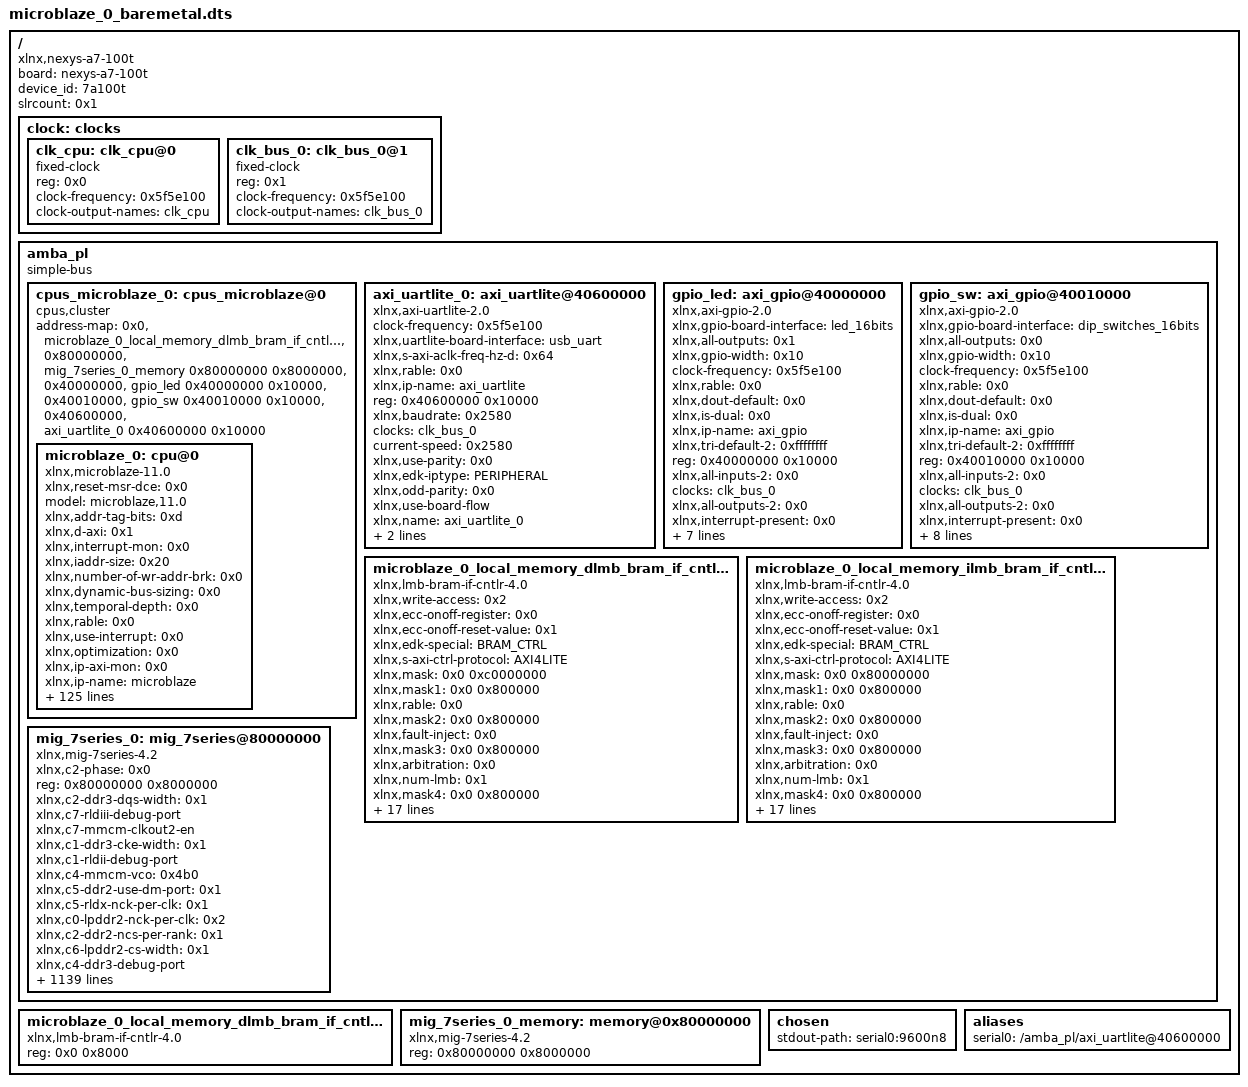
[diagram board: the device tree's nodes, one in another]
/dts-v1/;

/ {
        board = "nexys-a7-100t";
        compatible = "xlnx,nexys-a7-100t";
        device_id = "7a100t";
        #address-cells = <0x1>;
        #size-cells = <0x1>;
        slrcount = <0x1>;

        clock: clocks {
                #address-cells = <0x1>;
                #size-cells = <0x0>;
                phandle = <0x8>;

                clk_cpu: clk_cpu@0 {
                        compatible = "fixed-clock";
                        reg = <0x0>;
                        clock-frequency = <0x5f5e100>;
                        clock-output-names = "clk_cpu";
                        #clock-cells = <0x0>;
                        phandle = <0x9>;
                };

                clk_bus_0: clk_bus_0@1 {
                        compatible = "fixed-clock";
                        reg = <0x1>;
                        clock-frequency = <0x5f5e100>;
                        clock-output-names = "clk_bus_0";
                        #clock-cells = <0x0>;
                        phandle = <0x7>;
                };
        };

        amba_pl: amba_pl {
                ranges;
                compatible = "simple-bus";
                #address-cells = <0x1>;
                #size-cells = <0x1>;
                phandle = <0x6>;

                cpus_microblaze_0: cpus_microblaze@0 {
                        #cpu-mask-cells = <0x1>;
                        compatible = "cpus,cluster";
                        address-map = <0x0 &microblaze_0_local_memory_dlmb_bram_if_cntlr_memory 0x0 0x8000>,
                         <0x80000000 &mig_7series_0_memory 0x80000000 0x8000000>,
                         <0x40000000 &gpio_led 0x40000000 0x10000>,
                         <0x40010000 &gpio_sw 0x40010000 0x10000>,
                         <0x40600000 &axi_uartlite_0 0x40600000 0x10000>;
                        #ranges-address-cells = <0x1>;
                        #ranges-size-cells = <0x1>;
                        phandle = <0xa>;

                        microblaze_0: cpu@0 {
                                xlnx,reset-msr-dce = <0x0>;
                                model = "microblaze,11.0";
                                xlnx,addr-tag-bits = <0xd>;
                                xlnx,d-axi = <0x1>;
                                xlnx,interrupt-mon = <0x0>;
                                xlnx,iaddr-size = <0x20>;
                                xlnx,number-of-wr-addr-brk = <0x0>;
                                xlnx,dynamic-bus-sizing = <0x0>;
                                xlnx,temporal-depth = <0x0>;
                                xlnx,rable = <0x0>;
                                xlnx,use-interrupt = <0x0>;
                                xlnx,optimization = <0x0>;
                                xlnx,ip-axi-mon = <0x0>;
                                xlnx,ip-name = "microblaze";
                                d-cache-highaddr = <0x87ffffff>;
                                xlnx,dcache-force-tag-lutram = <0x0>;
                                xlnx,pc-width = <0x20>;
                                xlnx,interrupt-is-edge = <0x0>;
                                reg = <0x0>;
                                xlnx,async-interrupt = <0x1>;
                                xlnx,use-mmu = <0x0>;
                                xlnx,reset-msr-ee = <0x0>;
                                xlnx,icache-victims = <0x0>;
                                xlnx,use-reorder-instr = <0x1>;
                                xlnx,d-lmb-mon = <0x0>;
                                xlnx,d-lmb-protocol = <0x0>;
                                xlnx,ill-opcode-exception = <0x0>;
                                xlnx,dcache-always-used = <0x1>;
                                xlnx,use-div = <0x0>;
                                xlnx,dc-axi-mon = <0x0>;
                                xlnx,debug-trace-async-reset = <0x0>;
                                xlnx,trace = <0x0>;
                                xlnx,part = "xc7a100tcsg324-1";
                                i-cache-baseaddr = <0x80000000>;
                                xlnx,use-config-reset = <0x0>;
                                xlnx,pvr = <0x0>;
                                xlnx,i-lmb-mon = <0x0>;
                                xlnx,dcache-byte-size = <0x4000>;
                                xlnx,fault-tolerant = <0x0>;
                                xlnx,family = "artix7";
                                compatible = "xlnx,microblaze-11.0", "xlnx,microblaze";
                                xlnx,data-size = <0x20>;
                                xlnx,mmu-zones = <0x10>;
                                xlnx,debug-trace-size = <0x2000>;
                                xlnx,mmu-privileged-instr = <0x0>;
                                xlnx,enable-discrete-ports = <0x0>;
                                d-cache-line-size = <0x10>;
                                xlnx,d-lmb = <0x1>;
                                xlnx,sco = <0x0>;
                                xlnx,reset-msr-eip = <0x0>;
                                clock-frequency = <0x5f5e100>;
                                xlnx,debug-interface = <0x0>;
                                xlnx,use-ext-brk = <0x0>;
                                xlnx,daddr-size = <0x20>;
                                xlnx,debug-enabled = <0x1>;
                                xlnx,reset-msr-ice = <0x0>;
                                xlnx,num-sync-ff-dbg-trace-clk = <0x2>;
                                xlnx,i-lmb-protocol = <0x0>;
                                xlnx,endianness = <0x1>;
                                xlnx,fsl-exception = <0x0>;
                                i-cache-line-size = <0x10>;
                                xlnx,use-extended-fsl-instr = <0x0>;
                                xlnx,reset-msr = <0x0>;
                                xlnx,dp-axi-mon = <0x0>;
                                xlnx,branch-target-cache-size = <0x0>;
                                xlnx,dcache-use-writeback = <0x0>;
                                xlnx,div-zero-exception = <0x0>;
                                xlnx,mmu-tlb-access = <0x3>;
                                bus-handle = <0x6>;
                                xlnx,cache-byte-size = <0x4000>;
                                xlnx,pvr-user2 = <0x0>;
                                xlnx,opcode-0x0-illegal = <0x0>;
                                xlnx,icache-line-len = <0x4>;
                                xlnx,ecc-use-ce-exception = <0x0>;
                                xlnx,base-vectors = <0x0 0x0>;
                                xlnx,use-dcache = <0x1>;
                                xlnx,use-barrel = <0x0>;
                                xlnx,reset-msr-bip = <0x0>;
                                xlnx,edk-special = "microblaze";
                                xlnx,allow-dcache-wr = <0x1>;
                                xlnx,addr-size = <0x20>;
                                xlnx,debug-external-trace = <0x0>;
                                xlnx,piaddr-size = <0x20>;
                                i-cache-highaddr = <0x87ffffff>;
                                xlnx,num-sync-ff-clk-debug = <0x2>;
                                xlnx,debug-event-counters = <0x5>;
                                xlnx,fpu-exception = <0x0>;
                                xlnx,allow-icache-wr = <0x1>;
                                xlnx,i-axi = <0x0>;
                                xlnx,g-use-exceptions = <0x0>;
                                xlnx,icache-streams = <0x0>;
                                xlnx,g-template-list = <0x0>;
                                xlnx,dcache-line-len = <0x4>;
                                xlnx,num-sync-ff-clk = <0x2>;
                                xlnx,use-stack-protection = <0x0>;
                                xlnx,use-hw-mul = <0x0>;
                                xlnx,num-sync-ff-dbg-clk = <0x1>;
                                xlnx,interconnect = <0x2>;
                                xlnx,edk-iptype = "PROCESSOR";
                                i-cache-size = <0x4000>;
                                xlnx,debug-latency-counters = <0x1>;
                                xlnx,use-fpu = <0x0>;
                                xlnx,reset-msr-ie = <0x0>;
                                xlnx,edge-is-positive = <0x1>;
                                xlnx,use-pcmp-instr = <0x0>;
                                xlnx,use-icache = <0x1>;
                                d-cache-size = <0x4000>;
                                xlnx,async-wakeup = <0x3>;
                                xlnx,use-non-secure = <0x0>;
                                xlnx,dcache-addr-tag = <0xd>;
                                xlnx,number-of-rd-addr-brk = <0x0>;
                                d-cache-baseaddr = <0x80000000>;
                                xlnx,area-optimized = <0x0>;
                                xlnx,avoid-primitives = <0x0>;
                                xlnx,lockstep-slave = <0x0>;
                                xlnx,use-ext-nm-brk = <0x0>;
                                xlnx,instr-size = <0x20>;
                                xlnx,icache-always-used = <0x1>;
                                xlnx,i-lmb = <0x1>;
                                xlnx,mmu-dtlb-size = <0x4>;
                                xlnx,lockstep-select = <0x0>;
                                xlnx,lmb-data-size = <0x20>;
                                xlnx,ic-axi-mon = <0x0>;
                                xlnx,num-sync-ff-clk-irq = <0x1>;
                                xlnx,fsl-links = <0x0>;
                                timebase-frequency = <0x5f5e100>;
                                xlnx,icache-force-tag-lutram = <0x0>;
                                xlnx,dcache-data-width = <0x0>;
                                xlnx,dcache-victims = <0x0>;
                                xlnx,use-branch-target-cache = <0x0>;
                                xlnx,debug-profile-size = <0x0>;
                                xlnx,unaligned-exceptions = <0x0>;
                                xlnx,lockstep-master = <0x0>;
                                xlnx,freq = <0x5f5e100>;
                                xlnx,number-of-pc-brk = <0x1>;
                                xlnx,mmu-itlb-size = <0x2>;
                                xlnx,imprecise-exceptions = <0x0>;
                                xlnx,use-msr-instr = <0x0>;
                                xlnx,icache-data-width = <0x0>;
                                xlnx,debug-counter-width = <0x20>;
                                phandle = <0xb>;
                        };
                };

                axi_uartlite_0: axi_uartlite@40600000 {
                        compatible = "xlnx,axi-uartlite-2.0", "xlnx,xps-uartlite-1.00.a";
                        clock-frequency = <0x5f5e100>;
                        xlnx,uartlite-board-interface = "usb_uart";
                        xlnx,s-axi-aclk-freq-hz-d = <0x64>;
                        xlnx,rable = <0x0>;
                        xlnx,ip-name = "axi_uartlite";
                        reg = <0x40600000 0x10000>;
                        xlnx,baudrate = <0x2580>;
                        clocks = <&clk_bus_0>;
                        current-speed = <0x2580>;
                        xlnx,use-parity = <0x0>;
                        xlnx,edk-iptype = "PERIPHERAL";
                        xlnx,odd-parity = <0x0>;
                        status = "okay";
                        xlnx,use-board-flow;
                        xlnx,name = "axi_uartlite_0";
                        xlnx,data-bits = <0x8>;
                        xlnx,parity = "No_Parity";
                        phandle = <0x5>;
                };

                gpio_led: axi_gpio@40000000 {
                        xlnx,gpio-board-interface = "led_16bits";
                        compatible = "xlnx,axi-gpio-2.0", "xlnx,xps-gpio-1.00.a";
                        xlnx,all-outputs = <0x1>;
                        xlnx,gpio-width = <0x10>;
                        clock-frequency = <0x5f5e100>;
                        xlnx,rable = <0x0>;
                        xlnx,dout-default = <0x0>;
                        xlnx,is-dual = <0x0>;
                        xlnx,ip-name = "axi_gpio";
                        xlnx,tri-default-2 = <0xffffffff>;
                        reg = <0x40000000 0x10000>;
                        xlnx,all-inputs-2 = <0x0>;
                        clocks = <&clk_bus_0>;
                        xlnx,all-outputs-2 = <0x0>;
                        xlnx,interrupt-present = <0x0>;
                        xlnx,gpio2-board-interface = "Custom";
                        xlnx,edk-iptype = "PERIPHERAL";
                        xlnx,dout-default-2 = <0x0>;
                        xlnx,gpio2-width = <0x20>;
                        status = "okay";
                        clock-names = "s_axi_aclk";
                        xlnx,tri-default = <0xffffffff>;
                        xlnx,name = "gpio_led";
                        xlnx,all-inputs = <0x0>;
                        phandle = <0x3>;
                };

                gpio_sw: axi_gpio@40010000 {
                        xlnx,gpio-board-interface = "dip_switches_16bits";
                        compatible = "xlnx,axi-gpio-2.0", "xlnx,xps-gpio-1.00.a";
                        xlnx,all-outputs = <0x0>;
                        xlnx,gpio-width = <0x10>;
                        clock-frequency = <0x5f5e100>;
                        xlnx,rable = <0x0>;
                        xlnx,dout-default = <0x0>;
                        xlnx,is-dual = <0x0>;
                        xlnx,ip-name = "axi_gpio";
                        xlnx,tri-default-2 = <0xffffffff>;
                        reg = <0x40010000 0x10000>;
                        xlnx,all-inputs-2 = <0x0>;
                        clocks = <&clk_bus_0>;
                        xlnx,all-outputs-2 = <0x0>;
                        xlnx,interrupt-present = <0x0>;
                        xlnx,gpio2-board-interface = "Custom";
                        xlnx,edk-iptype = "PERIPHERAL";
                        xlnx,dout-default-2 = <0x0>;
                        xlnx,gpio2-width = <0x20>;
                        status = "okay";
                        clock-names = "s_axi_aclk";
                        xlnx,use-board-flow;
                        xlnx,tri-default = <0xffffffff>;
                        xlnx,name = "gpio_sw";
                        xlnx,all-inputs = <0x1>;
                        phandle = <0x4>;
                };

                microblaze_0_local_memory_dlmb_bram_if_cntlr: lmb_bram_if_cntlr@0 {
                        xlnx,write-access = <0x2>;
                        compatible = "xlnx,lmb-bram-if-cntlr-4.0";
                        xlnx,ecc-onoff-register = <0x0>;
                        xlnx,ecc-onoff-reset-value = <0x1>;
                        xlnx,edk-special = "BRAM_CTRL";
                        xlnx,s-axi-ctrl-protocol = "AXI4LITE";
                        xlnx,mask = <0x0 0xc0000000>;
                        xlnx,mask1 = <0x0 0x800000>;
                        xlnx,rable = <0x0>;
                        xlnx,mask2 = <0x0 0x800000>;
                        xlnx,fault-inject = <0x0>;
                        xlnx,mask3 = <0x0 0x800000>;
                        xlnx,arbitration = <0x0>;
                        xlnx,num-lmb = <0x1>;
                        xlnx,mask4 = <0x0 0x800000>;
                        reg = <0x0 0x8000>;
                        xlnx,s-axi-ctrl-addr-width = <0x20>;
                        xlnx,mask5 = <0x0 0x800000>;
                        xlnx,ecc-status-registers = <0x0>;
                        xlnx,mask6 = <0x0 0x800000>;
                        xlnx,lmb-protocol = <0x0>;
                        xlnx,ce-counter-width = <0x0>;
                        xlnx,mask7 = <0x0 0x800000>;
                        xlnx,ecc = <0x0>;
                        xlnx,lmb-dwidth = <0x20>;
                        xlnx,interconnect = <0x0>;
                        xlnx,ce-failing-registers = <0x0>;
                        xlnx,edk-iptype = "PERIPHERAL";
                        xlnx,ue-failing-registers = <0x0>;
                        xlnx,s-axi-ctrl-data-width = <0x20>;
                        xlnx,bram-awidth = <0x20>;
                        xlnx,lmb-awidth = <0x20>;
                        phandle = <0xc>;
                };

                microblaze_0_local_memory_ilmb_bram_if_cntlr: lmb_bram_if_cntlr@1 {
                        xlnx,write-access = <0x2>;
                        compatible = "xlnx,lmb-bram-if-cntlr-4.0";
                        xlnx,ecc-onoff-register = <0x0>;
                        xlnx,ecc-onoff-reset-value = <0x1>;
                        xlnx,edk-special = "BRAM_CTRL";
                        xlnx,s-axi-ctrl-protocol = "AXI4LITE";
                        xlnx,mask = <0x0 0x80000000>;
                        xlnx,mask1 = <0x0 0x800000>;
                        xlnx,rable = <0x0>;
                        xlnx,mask2 = <0x0 0x800000>;
                        xlnx,fault-inject = <0x0>;
                        xlnx,mask3 = <0x0 0x800000>;
                        xlnx,arbitration = <0x0>;
                        xlnx,num-lmb = <0x1>;
                        xlnx,mask4 = <0x0 0x800000>;
                        reg = <0x0 0x8000>;
                        xlnx,s-axi-ctrl-addr-width = <0x20>;
                        xlnx,mask5 = <0x0 0x800000>;
                        xlnx,ecc-status-registers = <0x0>;
                        xlnx,mask6 = <0x0 0x800000>;
                        xlnx,lmb-protocol = <0x0>;
                        xlnx,ce-counter-width = <0x0>;
                        xlnx,mask7 = <0x0 0x800000>;
                        xlnx,ecc = <0x0>;
                        xlnx,lmb-dwidth = <0x20>;
                        xlnx,interconnect = <0x0>;
                        xlnx,ce-failing-registers = <0x0>;
                        xlnx,edk-iptype = "PERIPHERAL";
                        xlnx,ue-failing-registers = <0x0>;
                        xlnx,s-axi-ctrl-data-width = <0x20>;
                        xlnx,bram-awidth = <0x20>;
                        xlnx,lmb-awidth = <0x20>;
                        phandle = <0xd>;
                };

                mig_7series_0: mig_7series@80000000 {
                        xlnx,c2-phase = <0x0>;
                        reg = <0x80000000 0x8000000>;
                        xlnx,c2-ddr3-dqs-width = <0x1>;
                        xlnx,c7-rldiii-debug-port;
                        xlnx,c7-mmcm-clkout2-en;
                        xlnx,c1-ddr3-cke-width = <0x1>;
                        xlnx,c1-rldii-debug-port;
                        xlnx,c4-mmcm-vco = <0x4b0>;
                        xlnx,c5-ddr2-use-dm-port = <0x1>;
                        xlnx,c5-rldx-nck-per-clk = <0x1>;
                        xlnx,c0-lpddr2-nck-per-clk = <0x2>;
                        xlnx,c2-ddr2-ncs-per-rank = <0x1>;
                        xlnx,c6-lpddr2-cs-width = <0x1>;
                        xlnx,c4-ddr3-debug-port;
                        xlnx,c4-lpddr2-dqs-cnt-width = <0x1>;
                        xlnx,c5-ddr2-use-cs-port = <0x1>;
                        xlnx,mmcm-clkout0-en;
                        xlnx,ddr2-addr-width = <0x1b>;
                        xlnx,c1-phase = <0x0>;
                        xlnx,c4-ddr3-odt-width = <0x1>;
                        xlnx,c5-rldiii-dk-width = <0x1>;
                        xlnx,c6-lpddr2-debug-port;
                        xlnx,c7-ddr2-dqs-width = <0x1>;
                        xlnx,c0-rldiii-ck-width = <0x1>;
                        xlnx,c5-ddr3-data-width = <0x8>;
                        xlnx,c6-ddr2-cke-width = <0x1>;
                        xlnx,c3-lpddr2-nck-per-clk = <0x2>;
                        xlnx,c6-rldiii-addr-width = <0x1d>;
                        xlnx,c5-ddr3-bank-width = <0x3>;
                        xlnx,c7-c-s-axi-ctrl-id-width = <0x4>;
                        xlnx,c1-ddr3-dqs-cnt-width = <0x1>;
                        xlnx,c2-rldii-data-width = <0x12>;
                        xlnx,lpddr2-dm-width = <0x1>;
                        xlnx,c7-use-axi = <0x0>;
                        xlnx,c2-rldii-bank-width = <0x2>;
                        xlnx,c0-rldii-qvld-width = <0x1>;
                        xlnx,c3-ddr2-cs-width = <0x1>;
                        xlnx,c0-phase = <0x0>;
                        xlnx,c6-lpddr2-nck-per-clk = <0x2>;
                        xlnx,c3-lpddr2-dq-width = <0x8>;
                        xlnx,c5-lpddr2-addr-width = <0x8>;
                        xlnx,c5-lpddr2-reg-ctrl;
                        xlnx,c3-c-s-axi-ctrl-mem-size = <0x100000>;
                        xlnx,c4-ddr3-dqs-cnt-width = <0x1>;
                        xlnx,c6-ddr2-nck-per-clk = <0x2>;
                        xlnx,c4-qdriip-burst-len = <0x1>;
                        xlnx,mmcm-vco = <0x4b0>;
                        xlnx,ddr3-addr-width = <0x8>;
                        xlnx,c5-ddrx-addr-width = <0x8>;
                        xlnx,c5-mmcm-clkout1-en;
                        xlnx,c7-ddr3-dqs-cnt-width = <0x1>;
                        xlnx,c1-mmcm-vco = <0x4b0>;
                        xlnx,c4-ddr3-dq-width = <0x8>;
                        xlnx,c7-ddrx-nck-per-clk = <0x2>;
                        xlnx,c6-is-clk-shared;
                        xlnx,c0-mmcm-clkout4-en;
                        xlnx,c3-rldiii-qk-width = <0x8>;
                        xlnx,c7-rldii-num-devices = <0x1>;
                        xlnx,c0-sysclk-type = "DIFF";
                        xlnx,c1-qdriip-debug-port;
                        xlnx,c0-freq-hz = <0x64>;
                        xlnx,c0-ddr3-use-dm-port = <0x1>;
                        xlnx,rldii-nck-per-clk = <0x1>;
                        xlnx,c1-is-clk-shared;
                        xlnx,c0-mmcm-clkout4-freq = <0xa>;
                        xlnx,c4-lpddr2-cke-width = <0x1>;
                        xlnx,c4-rldx-dm-width = <0x1>;
                        xlnx,c5-ddr3-ck-width = <0x1>;
                        xlnx,c7-qdriip-bw-width = <0x8>;
                        xlnx,c0-ui-extra-clocks;
                        xlnx,c0-ddr3-use-cs-port = <0x1>;
                        xlnx,c4-rldii-nck-per-clk = <0x1>;
                        xlnx,c0-mmcm-clkout1-freq = <0xa>;
                        xlnx,reset-board-interface = "reset";
                        xlnx,ddr2-dqs-width = <0x2>;
                        xlnx,c0-qdriip-addr-width = <0x1d>;
                        xlnx,c6-ddr2-reg-ctrl;
                        xlnx,rldii-data-width = <0x12>;
                        xlnx,lpddr2-cs-width = <0x1>;
                        xlnx,rldii-bank-width = <0x2>;
                        xlnx,c4-ddr2-row-width = <0xe>;
                        xlnx,c3-rldii-cmd-per-clk = <0x1>;
                        xlnx,c0-ddr3-ck-width = <0x1>;
                        xlnx,is-clk-shared;
                        xlnx,c2-rldx-addr-width = <0x1d>;
                        xlnx,c1-ddr2-reg-ctrl;
                        xlnx,c4-ddrx-data-width = <0x8>;
                        xlnx,c0-rldiii-debug-port;
                        xlnx,c3-ddr2-addr-width = <0x8>;
                        xlnx,c3-mmcm-clkout0-en;
                        xlnx,c4-rldii-rld-addr-width = <0x1d>;
                        xlnx,c5-c-s-axi-ctrl-addr-width = <0x20>;
                        xlnx,c7-c-s-axi-id-width = <0x4>;
                        xlnx,c1-ddr3-nck-per-clk = <0x2>;
                        xlnx,c4-rldx-cmd-per-clk = <0x1>;
                        xlnx,c0-ecc;
                        xlnx,c3-rldii-qk-width = <0x8>;
                        xlnx,c3-lpddr2-dm-width = <0x1>;
                        xlnx,ddr2-reg-ctrl;
                        xlnx,c7-ddr3-cke-width = <0x1>;
                        xlnx,c0-rldii-addr-width = <0x1d>;
                        xlnx,c6-mmcm-clkout3-en;
                        xlnx,c3-dqs-cnt-width = <0x1>;
                        xlnx,c0-c-s-axi-mem-size = <0x100000>;
                        xlnx,c1-mmcm-clkout3-freq = <0xa>;
                        xlnx,c5-ddr3-ncs-per-rank = <0x1>;
                        xlnx,c7-lpddr2-data-width = <0x8>;
                        xlnx,c4-ddr3-dm-width = <0x1>;
                        xlnx,c7-lpddr2-bank-width = <0x3>;
                        xlnx,c1-mmcm-clkout0-freq = <0xa>;
                        xlnx,c3-ddr3-addr-width = <0x8>;
                        xlnx,c5-lpddr2-row-width = <0xe>;
                        xlnx,c2-ddr2-use-dm-port = <0x1>;
                        xlnx,c2-rldx-nck-per-clk = <0x1>;
                        xlnx,c2-rldiii-dm-width = <0x1>;
                        xlnx,c1-ddr2-debug-port;
                        xlnx,c2-ddr2-use-cs-port = <0x1>;
                        xlnx,c1-rldx-data-width = <0x12>;
                        xlnx,c2-ddr2-dqs-width = <0x1>;
                        xlnx,c4-rldii-ck-width = <0x1>;
                        xlnx,c1-rldx-bank-width = <0x2>;
                        xlnx,c7-ddr2-dq-width = <0x8>;
                        xlnx,c1-ddr2-cke-width = <0x1>;
                        xlnx,c2-ddr2-data-width = <0x8>;
                        xlnx,c2-ddr2-bank-width = <0x3>;
                        xlnx,c5-ddr2-ncs-per-rank = <0x1>;
                        xlnx,c5-ecc;
                        xlnx,c0-rldii-num-devices = <0x1>;
                        xlnx,c4-ddr2-odt-width = <0x1>;
                        xlnx,c5-freq-hz = <0x64>;
                        xlnx,c2-ddr2-dq-width = <0x8>;
                        xlnx,c6-lpddr2-ck-width = <0x1>;
                        xlnx,c2-ddr3-use-odt-port = <0x1>;
                        xlnx,c4-mmcm-clkout2-en;
                        xlnx,c1-qdriip-burst-len = <0x1>;
                        xlnx,c3-ddr2-nck-per-clk = <0x2>;
                        xlnx,c3-lpddr2-cs-width = <0x1>;
                        xlnx,c1-ddr3-debug-port;
                        xlnx,c2-rldiii-num-devices = <0x1>;
                        xlnx,c5-rldii-dm-width = <0x1>;
                        xlnx,c2-qdriip-data-width = <0x12>;
                        xlnx,c2-mmcm-clkout2-freq = <0xa>;
                        xlnx,c2-rldiii-dk-width = <0x1>;
                        xlnx,c2-rldiii-qvld-width = <0x1>;
                        xlnx,ddr3-cke-width = <0x1>;
                        xlnx,c1-rldiii-rld-addr-width = <0x1d>;
                        xlnx,c2-ddr3-data-width = <0x8>;
                        xlnx,use-axi = <0x1>;
                        xlnx,c5-ddr3-row-width = <0xe>;
                        xlnx,c1-lpddr2-dqs-cnt-width = <0x1>;
                        xlnx,c1-use-axi = <0x0>;
                        xlnx,c2-ddr3-bank-width = <0x3>;
                        xlnx,c3-ddr2-ck-width = <0x1>;
                        xlnx,c5-rldiii-num-devices = <0x1>;
                        xlnx,c6-lpddr2-dqs-width = <0x1>;
                        xlnx,c4-ddr3-cs-width = <0x1>;
                        xlnx,c4-ddrx-nck-per-clk = <0x2>;
                        xlnx,c5-rldiii-ck-width = <0x1>;
                        xlnx,mmcm-clkout3-en;
                        xlnx,c5-sysclk-type = "DIFF";
                        xlnx,rldx-nck-per-clk = <0x1>;
                        xlnx,ddr2-use-dm-port = <0x1>;
                        xlnx,c2-ddr2-use-odt-port = <0x1>;
                        xlnx,c0-lpddr2-dq-width = <0x8>;
                        xlnx,c2-lpddr2-reg-ctrl;
                        xlnx,ddr2-use-cs-port = <0x1>;
                        xlnx,c1-lpddr2-cke-width = <0x1>;
                        xlnx,qdriip-debug-port;
                        xlnx,c2-ddrx-addr-width = <0x8>;
                        xlnx,c1-rldiii-data-width = <0x12>;
                        xlnx,c5-rldii-dk-width = <0x1>;
                        xlnx,c4-qdriip-debug-port;
                        xlnx,lpddr2-dqs-cnt-width = <0x1>;
                        xlnx,c1-rldiii-bank-width = <0x2>;
                        xlnx,c2-mmcm-clkout1-en;
                        xlnx,c0-c-s-axi-data-width = <0x20>;
                        xlnx,c0-rldiii-qk-width = <0x8>;
                        xlnx,c3-mmcm-clkout4-freq = <0xa>;
                        xlnx,c0-lpddr2-data-width = <0x8>;
                        xlnx,c7-ddr2-dm-width = <0x1>;
                        xlnx,c0-lpddr2-bank-width = <0x3>;
                        xlnx,c7-rldii-nck-per-clk = <0x1>;
                        xlnx,c6-rldii-debug-port;
                        xlnx,c3-mmcm-clkout1-freq = <0xa>;
                        xlnx,c2-c-s-axi-addr-width = <0x20>;
                        xlnx,c3-c-s-axi-data-width = <0x20>;
                        xlnx,c3-qdriip-addr-width = <0x1d>;
                        xlnx,c5-mmcm-clkout4-en;
                        xlnx,c4-c-s-axi-id-width = <0x4>;
                        xlnx,c6-rldii-cmd-per-clk = <0x1>;
                        xlnx,c6-c-s-axi-ctrl-data-width = <0x20>;
                        xlnx,c1-rldx-cmd-per-clk = <0x1>;
                        xlnx,lpddr2-ck-width = <0x1>;
                        xlnx,c4-qdriip-bw-width = <0x8>;
                        xlnx,c7-ddr3-reg-ctrl;
                        xlnx,c2-ddr2-dm-width = <0x1>;
                        xlnx,c3-ddr3-dqs-width = <0x1>;
                        xlnx,c6-c-s-axi-data-width = <0x20>;
                        xlnx,c2-ddr3-cke-width = <0x1>;
                        xlnx,c5-c-s-axi-addr-width = <0x20>;
                        xlnx,c3-rldiii-debug-port;
                        xlnx,c7-rldii-data-width = <0x12>;
                        xlnx,c6-rldiii-rld-addr-width = <0x1d>;
                        xlnx,c4-c-s-axi-ctrl-id-width = <0x4>;
                        xlnx,s-axi-ctrl-mem-size = <0x100000>;
                        xlnx,c5-ui-extra-clocks;
                        xlnx,c7-rldii-bank-width = <0x2>;
                        xlnx,c5-rldii-qvld-width = <0x1>;
                        xlnx,c5-ddr3-odt-width = <0x1>;
                        xlnx,c2-ddr3-reg-ctrl;
                        xlnx,qdriip-num-devices = <0x1>;
                        xlnx,c1-ddrx-data-width = <0x8>;
                        xlnx,ddr2-dqs-cnt-width = <0x1>;
                        xlnx,c7-ddr2-cke-width = <0x1>;
                        xlnx,c0-c-s-axi-ctrl-mem-size = <0x100000>;
                        xlnx,c2-lpddr2-debug-port;
                        xlnx,c0-mmcm-clkout0-en;
                        xlnx,c0-ddr2-addr-width = <0x8>;
                        xlnx,c2-lpddr2-row-width = <0xe>;
                        xlnx,c2-rldiii-addr-width = <0x1d>;
                        xlnx,c3-c-s-axi-ctrl-addr-width = <0x20>;
                        xlnx,c7-rldx-addr-width = <0x1d>;
                        xlnx,mmcm-clkout3-freq = <0x47868c00>;
                        xlnx,c1-rldii-rld-addr-width = <0x1d>;
                        xlnx,c6-use-axi = <0x0>;
                        xlnx,c0-lpddr2-dm-width = <0x1>;
                        xlnx,c4-mmcm-clkout3-freq = <0xa>;
                        xlnx,mmcm-clkout0-freq = <0xbebc200>;
                        xlnx,c1-lpddr2-addr-width = <0x8>;
                        xlnx,c3-mmcm-clkout3-en;
                        xlnx,c4-mmcm-clkout0-freq = <0xa>;
                        xlnx,c7-ddr2-cs-width = <0x1>;
                        xlnx,c1-qdriip-num-devices = <0x1>;
                        xlnx,c1-ddr2-dqs-cnt-width = <0x1>;
                        xlnx,c0-ddr3-addr-width = <0x8>;
                        xlnx,c5-ddr3-use-dm-port = <0x1>;
                        xlnx,c2-ddr2-cs-width = <0x1>;
                        xlnx,c0-rldii-dm-width = <0x1>;
                        xlnx,rldii-rld-addr-width = <0x1d>;
                        xlnx,c0-ddr2-nck-per-clk = <0x2>;
                        xlnx,c5-ddr3-use-cs-port = <0x1>;
                        xlnx,c4-qdriip-num-devices = <0x1>;
                        xlnx,c3-rldii-num-devices = <0x1>;
                        xlnx,c4-ddr2-dqs-cnt-width = <0x1>;
                        xlnx,c7-rldiii-dm-width = <0x1>;
                        xlnx,c0-ddr3-row-width = <0xe>;
                        xlnx,c6-ddr2-debug-port;
                        xlnx,c5-ddr3-use-odt-port = <0x1>;
                        xlnx,c6-rldx-data-width = <0x12>;
                        xlnx,c6-mem-type = "DDR3";
                        xlnx,c7-qdriip-num-devices = <0x1>;
                        xlnx,c3-lpddr2-dqs-width = <0x1>;
                        xlnx,c6-rldx-bank-width = <0x2>;
                        xlnx,c7-ddr2-dqs-cnt-width = <0x1>;
                        xlnx,c7-ddr2-data-width = <0x8>;
                        xlnx,c1-ddrx-nck-per-clk = <0x2>;
                        xlnx,c3-ddr3-dq-width = <0x8>;
                        xlnx,c0-rldii-nck-per-clk = <0x1>;
                        xlnx,ddr2-cke-width = <0x1>;
                        xlnx,c7-ddr2-bank-width = <0x3>;
                        xlnx,lpddr2-row-width = <0xe>;
                        xlnx,c5-qdriip-data-width = <0x12>;
                        xlnx,c3-lpddr2-ck-width = <0x1>;
                        xlnx,c5-ddr2-row-width = <0xe>;
                        xlnx,c5-mmcm-clkout2-freq = <0xa>;
                        xlnx,c5-rldiii-qvld-width = <0x1>;
                        xlnx,c1-mmcm-clkout2-en;
                        xlnx,c5-is-clk-shared;
                        xlnx,c5-c-s-axi-ctrl-mem-size = <0x100000>;
                        xlnx,c6-ddr3-nck-per-clk = <0x2>;
                        xlnx,c0-lpddr2-cs-width = <0x1>;
                        xlnx,s-axi-ctrl-addr-width = <0x20>;
                        xlnx,c5-polarity = "ACTIVE_LOW";
                        xlnx,c2-rldiii-nck-per-clk = <0x1>;
                        xlnx,c0-rldii-dk-width = <0x1>;
                        xlnx,c5-rldii-addr-width = <0x1d>;
                        xlnx,c0-is-clk-shared;
                        xlnx,c3-rldx-dm-width = <0x1>;
                        xlnx,c6-ddr3-debug-port;
                        xlnx,c4-ddr3-ck-width = <0x1>;
                        xlnx,c5-ddr2-use-odt-port = <0x1>;
                        xlnx,c5-c-s-axi-mem-size = <0x100000>;
                        xlnx,c7-rldiii-dk-width = <0x1>;
                        xlnx,c4-rldii-qk-width = <0x8>;
                        xlnx,c5-ddr2-reg-ctrl;
                        xlnx,c5-rldiii-nck-per-clk = <0x1>;
                        xlnx,c2-rldiii-ck-width = <0x1>;
                        xlnx,c7-ddr3-data-width = <0x8>;
                        xlnx,rldiii-data-width = <0x12>;
                        xlnx,c1-sysclk-type = "DIFF";
                        xlnx,c7-ddr3-bank-width = <0x3>;
                        xlnx,rldiii-bank-width = <0x2>;
                        xlnx,c7-rldx-nck-per-clk = <0x1>;
                        xlnx,c7-ddr2-use-dm-port = <0x1>;
                        xlnx,c3-rldii-debug-port;
                        xlnx,c4-rldiii-data-width = <0x12>;
                        xlnx,c7-qdriip-debug-port;
                        xlnx,c4-rldiii-bank-width = <0x2>;
                        xlnx,c0-ddr2-reg-ctrl;
                        xlnx,c3-mem-type = "DDR3";
                        xlnx,c7-ddr2-use-cs-port = <0x1>;
                        xlnx,c1-c-s-axi-id-width = <0x4>;
                        xlnx,c7-lpddr2-reg-ctrl;
                        xlnx,c1-ddr3-ncs-per-rank = <0x1>;
                        xlnx,c5-lpddr2-dq-width = <0x8>;
                        xlnx,c7-dqs-cnt-width = <0x1>;
                        xlnx,c6-mmcm-clkout4-freq = <0xa>;
                        xlnx,c3-lpddr2-data-width = <0x8>;
                        xlnx,c3-lpddr2-bank-width = <0x3>;
                        xlnx,c6-mmcm-clkout1-freq = <0xa>;
                        xlnx,c6-qdriip-addr-width = <0x1d>;
                        xlnx,c2-lpddr2-use-dm-port = <0x1>;
                        xlnx,c4-rldii-data-width = <0x12>;
                        xlnx,c7-ddrx-addr-width = <0x8>;
                        xlnx,c0-ddr3-odt-width = <0x1>;
                        xlnx,c2-polarity = "ACTIVE_LOW";
                        xlnx,c4-rldii-bank-width = <0x2>;
                        xlnx,c2-rldii-qvld-width = <0x1>;
                        xlnx,c7-mmcm-clkout1-en;
                        xlnx,c0-rldiii-cmd-per-clk = <0x1>;
                        xlnx,c2-dqs-cnt-width = <0x1>;
                        xlnx,c2-lpddr2-use-cs-port = <0x1>;
                        xlnx,c3-ddr2-dqs-width = <0x1>;
                        xlnx,c5-rldii-ck-width = <0x1>;
                        xlnx,ddr2-debug-port;
                        xlnx,c2-ddr2-cke-width = <0x1>;
                        xlnx,rldx-data-width = <0x12>;
                        xlnx,c2-mmcm-clkout4-en;
                        xlnx,c5-lpddr2-use-dm-port = <0x1>;
                        xlnx,rldx-bank-width = <0x2>;
                        xlnx,c6-qdriip-burst-len = <0x1>;
                        xlnx,c5-rldiii-qk-width = <0x8>;
                        xlnx,c6-rldiii-debug-port;
                        xlnx,c5-lpddr2-dqs-cnt-width = <0x1>;
                        xlnx,c5-ddr2-odt-width = <0x1>;
                        xlnx,c1-ddr2-ncs-per-rank = <0x1>;
                        xlnx,c3-ddr3-dm-width = <0x1>;
                        xlnx,c3-rldiii-cmd-per-clk = <0x1>;
                        xlnx,c4-c-s-axi-ctrl-data-width = <0x20>;
                        xlnx,c5-lpddr2-use-cs-port = <0x1>;
                        xlnx,c1-qdriip-bw-width = <0x8>;
                        xlnx,c3-ecc;
                        xlnx,c4-freq-hz = <0x64>;
                        xlnx,c5-lpddr2-debug-port;
                        xlnx,c6-rldii-dm-width = <0x1>;
                        xlnx,c2-ui-extra-clocks;
                        xlnx,c0-mem-type = "DDR3";
                        xlnx,c6-rldiii-cmd-per-clk = <0x1>;
                        xlnx,c5-rldiii-addr-width = <0x1d>;
                        xlnx,c6-ddr2-dq-width = <0x8>;
                        xlnx,ddr3-debug-port;
                        xlnx,lpddr2-nck-per-clk = <0x2>;
                        xlnx,lpddr2-addr-width = <0x8>;
                        xlnx,c6-ddr3-row-width = <0xe>;
                        xlnx,c7-mmcm-clkout3-freq = <0xa>;
                        xlnx,c2-ddr3-use-dm-port = <0x1>;
                        xlnx,c4-lpddr2-addr-width = <0x8>;
                        xlnx,c1-c-s-axi-ctrl-addr-width = <0x20>;
                        xlnx,c7-mmcm-clkout0-freq = <0xa>;
                        xlnx,c6-lpddr2-cke-width = <0x1>;
                        xlnx,c4-rldx-addr-width = <0x1d>;
                        xlnx,c6-ddrx-data-width = <0x8>;
                        xlnx,c1-ddr2-dq-width = <0x8>;
                        xlnx,c0-use-axi = <0x0>;
                        xlnx,c5-mmcm-vco = <0x4b0>;
                        xlnx,c2-ddr3-use-cs-port = <0x1>;
                        xlnx,c5-ddr2-addr-width = <0x8>;
                        xlnx,c5-mmcm-clkout0-en;
                        xlnx,c7-ddr2-ck-width = <0x1>;
                        xlnx,c0-mmcm-clkout3-en;
                        xlnx,rldii-qvld-width = <0x1>;
                        xlnx,c5-lpddr2-dm-width = <0x1>;
                        xlnx,rldiii-rld-addr-width = <0x1d>;
                        xlnx,c0-lpddr2-dqs-width = <0x1>;
                        xlnx,temp-mon-control = "INTERNAL";
                        xlnx,ddr2-dq-width = <0x10>;
                        xlnx,c6-rldii-dk-width = <0x1>;
                        xlnx,mig-dont-touch-param = "Custom";
                        xlnx,c1-lpddr2-nck-per-clk = <0x2>;
                        xlnx,c0-ddr2-row-width = <0xe>;
                        xlnx,c2-ddr2-ck-width = <0x1>;
                        xlnx,c6-rldii-num-devices = <0x1>;
                        xlnx,c0-qdriip-debug-port;
                        xlnx,c3-ddr3-cs-width = <0x1>;
                        xlnx,edk-iptype = "PERIPHERAL";
                        xlnx,c6-rldx-cmd-per-clk = <0x1>;
                        xlnx,c3-ddr3-nck-per-clk = <0x2>;
                        xlnx,c5-ddr3-addr-width = <0x8>;
                        xlnx,c4-lpddr2-nck-per-clk = <0x2>;
                        xlnx,c2-ddr3-dqs-cnt-width = <0x1>;
                        xlnx,c2-rldii-addr-width = <0x1d>;
                        xlnx,c3-rldii-nck-per-clk = <0x1>;
                        xlnx,c1-c-s-axi-ctrl-id-width = <0x4>;
                        xlnx,c3-rldiii-rld-addr-width = <0x1d>;
                        xlnx,c4-rldiii-dm-width = <0x1>;
                        xlnx,c3-ddr2-debug-port;
                        xlnx,c2-c-s-axi-mem-size = <0x100000>;
                        xlnx,c2-mmcm-vco = <0x4b0>;
                        xlnx,c3-rldx-data-width = <0x12>;
                        xlnx,c2-rldii-cmd-per-clk = <0x1>;
                        xlnx,c7-lpddr2-nck-per-clk = <0x2>;
                        xlnx,c3-rldx-bank-width = <0x2>;
                        xlnx,c4-ddr3-dqs-width = <0x1>;
                        xlnx,c4-ddr2-data-width = <0x8>;
                        xlnx,c3-ddr3-cke-width = <0x1>;
                        xlnx,c5-rldii-rld-addr-width = <0x1d>;
                        xlnx,c6-sysclk-type = "DIFF";
                        xlnx,c4-ddr2-bank-width = <0x3>;
                        xlnx,c5-ddr3-dqs-cnt-width = <0x1>;
                        xlnx,ddr3-use-dm-port = <0x1>;
                        xlnx,c0-lpddr2-ck-width = <0x1>;
                        xlnx,c7-lpddr2-row-width = <0xe>;
                        xlnx,c0-rldii-debug-port;
                        xlnx,c4-ddr2-use-dm-port = <0x1>;
                        xlnx,c4-rldx-nck-per-clk = <0x1>;
                        xlnx,ddr3-use-cs-port = <0x1>;
                        xlnx,c6-ddr3-odt-width = <0x1>;
                        xlnx,c6-ddr2-dm-width = <0x1>;
                        xlnx,c4-ddr2-use-cs-port = <0x1>;
                        xlnx,c6-mmcm-clkout2-en;
                        xlnx,c5-lpddr2-cs-width = <0x1>;
                        xlnx,ddrx-data-width = <0x8>;
                        xlnx,c3-ddr3-debug-port;
                        xlnx,c7-rldiii-data-width = <0x12>;
                        xlnx,c6-ddr3-reg-ctrl;
                        xlnx,c1-ddr2-dm-width = <0x1>;
                        xlnx,c1-rldii-data-width = <0x12>;
                        xlnx,c7-rldiii-bank-width = <0x2>;
                        compatible = "xlnx,mig-7series-4.2";
                        xlnx,c4-rldiii-dk-width = <0x1>;
                        xlnx,ddr3-ncs-per-rank = <0x1>;
                        xlnx,c1-rldii-bank-width = <0x2>;
                        xlnx,c0-rldii-ck-width = <0x1>;
                        xlnx,c4-ddr3-data-width = <0x8>;
                        xlnx,c0-mmcm-clkout3-freq = <0xa>;
                        xlnx,c4-ddr3-bank-width = <0x3>;
                        xlnx,c4-ddr3-ncs-per-rank = <0x1>;
                        xlnx,c5-use-axi = <0x0>;
                        xlnx,c6-lpddr2-data-width = <0x8>;
                        xlnx,c1-ddr3-reg-ctrl;
                        xlnx,c7-rldiii-ck-width = <0x1>;
                        xlnx,c6-lpddr2-bank-width = <0x3>;
                        xlnx,c0-mmcm-clkout0-freq = <0xa>;
                        xlnx,c0-ddr2-odt-width = <0x1>;
                        xlnx,c3-qdriip-burst-len = <0x1>;
                        xlnx,c5-ddr2-nck-per-clk = <0x2>;
                        xlnx,ddr2-dm-width = <0x2>;
                        xlnx,rldii-addr-width = <0x1d>;
                        xlnx,c2-lpddr2-dq-width = <0x8>;
                        xlnx,c4-lpddr2-reg-ctrl;
                        xlnx,lpddr2-ncs-per-rank = <0x1>;
                        xlnx,c1-rldii-dm-width = <0x1>;
                        xlnx,c6-c-s-axi-ctrl-id-width = <0x4>;
                        xlnx,ddr3-reg-ctrl;
                        xlnx,ddr2-ncs-per-rank = <0x1>;
                        xlnx,c4-ddrx-addr-width = <0x8>;
                        xlnx,c6-ddrx-nck-per-clk = <0x2>;
                        xlnx,c4-ddr2-ncs-per-rank = <0x1>;
                        xlnx,c4-mmcm-clkout1-en;
                        xlnx,c1-ddr3-row-width = <0xe>;
                        xlnx,c6-ddr2-cs-width = <0x1>;
                        xlnx,c2-c-s-axi-ctrl-mem-size = <0x100000>;
                        xlnx,c2-rldiii-qk-width = <0x8>;
                        xlnx,c1-ddr3-use-odt-port = <0x1>;
                        xlnx,c3-lpddr2-cke-width = <0x1>;
                        xlnx,c2-c-s-axi-ctrl-data-width = <0x20>;
                        xlnx,c7-mmcm-clkout4-en;
                        xlnx,c6-ddr2-row-width = <0xe>;
                        xlnx,c1-ddr2-cs-width = <0x1>;
                        xlnx,c1-qdriip-data-width = <0x12>;
                        xlnx,c2-lpddr2-dqs-cnt-width = <0x1>;
                        xlnx,c1-mmcm-clkout2-freq = <0xa>;
                        xlnx,c1-rldiii-qvld-width = <0x1>;
                        xlnx,c6-qdriip-bw-width = <0x8>;
                        xlnx,mmcm-clkout2-en;
                        xlnx,c7-ddr3-dq-width = <0x8>;
                        xlnx,c7-lpddr2-addr-width = <0x8>;
                        xlnx,c1-rldii-dk-width = <0x1>;
                        xlnx,c0-debug-port;
                        xlnx,c7-ui-extra-clocks;
                        xlnx,ddr2-cs-width = <0x1>;
                        xlnx,c1-ddr2-use-odt-port = <0x1>;
                        xlnx,c2-ddr3-dq-width = <0x8>;
                        xlnx,c6-c-s-axi-id-width = <0x4>;
                        xlnx,c5-rldii-qk-width = <0x8>;
                        xlnx,c1-rldx-addr-width = <0x1d>;
                        xlnx,s-axi-id-width = <0x4>;
                        xlnx,c0-ddr3-nck-per-clk = <0x2>;
                        xlnx,c3-ddrx-data-width = <0x8>;
                        xlnx,c3-rldx-cmd-per-clk = <0x1>;
                        xlnx,c2-ddr2-addr-width = <0x8>;
                        xlnx,c2-mmcm-clkout0-en;
                        xlnx,c4-is-clk-shared;
                        xlnx,c7-rldx-dm-width = <0x1>;
                        xlnx,c0-rldiii-data-width = <0x12>;
                        xlnx,c0-rldiii-num-devices = <0x1>;
                        xlnx,c3-qdriip-debug-port;
                        xlnx,c0-rldiii-bank-width = <0x2>;
                        xlnx,c7-rldii-qvld-width = <0x1>;
                        xlnx,c2-lpddr2-dm-width = <0x1>;
                        xlnx,c2-rldx-dm-width = <0x1>;
                        xlnx,c3-ddr3-ck-width = <0x1>;
                        xlnx,c5-mmcm-clkout3-en;
                        xlnx,c1-debug-port;
                        xlnx,c2-mmcm-clkout4-freq = <0xa>;
                        xlnx,c3-rldiii-num-devices = <0x1>;
                        xlnx,c4-ddr2-reg-ctrl;
                        xlnx,c6-rldii-nck-per-clk = <0x1>;
                        xlnx,c4-lpddr2-row-width = <0xe>;
                        xlnx,c7-c-s-axi-ctrl-mem-size = <0x100000>;
                        xlnx,c1-ddr3-odt-width = <0x1>;
                        xlnx,c1-ddr2-use-dm-port = <0x1>;
                        xlnx,c1-rldx-nck-per-clk = <0x1>;
                        xlnx,c2-mmcm-clkout1-freq = <0xa>;
                        xlnx,c2-qdriip-addr-width = <0x1d>;
                        xlnx,c6-rldii-ck-width = <0x1>;
                        xlnx,c4-ddr2-dqs-width = <0x1>;
                        xlnx,c1-ddr2-use-cs-port = <0x1>;
                        xlnx,c2-ddr3-addr-width = <0x8>;
                        xlnx,c3-ddr2-cke-width = <0x1>;
                        xlnx,c5-rldii-cmd-per-clk = <0x1>;
                        xlnx,c6-rldiii-num-devices = <0x1>;
                        xlnx,c1-rldiii-dm-width = <0x1>;
                        xlnx,c0-ddr2-debug-port;
                        xlnx,c6-ddr2-odt-width = <0x1>;
                        xlnx,c6-dqs-cnt-width = <0x1>;
                        xlnx,c2-rldiii-debug-port;
                        xlnx,c0-rldx-data-width = <0x12>;
                        xlnx,c0-rldx-bank-width = <0x2>;
                        xlnx,c1-ddr2-data-width = <0x8>;
                        xlnx,c2-sysclk-type = "DIFF";
                        xlnx,c1-ddr2-bank-width = <0x3>;
                        xlnx,c2-debug-port;
                        xlnx,qdriip-bw-width = <0x8>;
                        xlnx,c1-ecc;
                        xlnx,c7-rldii-dm-width = <0x1>;
                        xlnx,c7-ddr3-use-dm-port = <0x1>;
                        xlnx,c7-ddr3-dm-width = <0x1>;
                        xlnx,c1-lpddr2-debug-port;
                        xlnx,c1-dqs-cnt-width = <0x1>;
                        xlnx,c3-freq-hz = <0x64>;
                        xlnx,c0-qdriip-burst-len = <0x1>;
                        xlnx,c2-ddr2-nck-per-clk = <0x2>;
                        xlnx,c2-rldii-rld-addr-width = <0x1d>;
                        xlnx,c7-ddr3-use-cs-port = <0x1>;
                        xlnx,c1-rldiii-addr-width = <0x1d>;
                        xlnx,c5-lpddr2-ck-width = <0x1>;
                        xlnx,c7-ddr3-row-width = <0xe>;
                        xlnx,c3-mmcm-clkout2-en;
                        xlnx,c1-c-s-axi-data-width = <0x20>;
                        xlnx,c0-c-s-axi-addr-width = <0x20>;
                        xlnx,c7-ddr3-ncs-per-rank = <0x1>;
                        xlnx,c2-ddr3-dm-width = <0x1>;
                        xlnx,c2-lpddr2-cs-width = <0x1>;
                        xlnx,c3-mmcm-clkout3-freq = <0xa>;
                        xlnx,c0-ddr3-debug-port;
                        xlnx,c0-lpddr2-addr-width = <0x8>;
                        xlnx,dqs-cnt-width = <0x1>;
                        xlnx,c1-rldiii-dk-width = <0x1>;
                        xlnx,c3-mmcm-clkout0-freq = <0xa>;
                        xlnx,c5-lpddr2-dqs-width = <0x1>;
                        xlnx,c3-ddrx-nck-per-clk = <0x2>;
                        xlnx,c1-ddr3-data-width = <0x8>;
                        xlnx,c3-c-s-axi-addr-width = <0x20>;
                        xlnx,c4-c-s-axi-data-width = <0x20>;
                        xlnx,c1-ddr3-bank-width = <0x3>;
                        xlnx,c3-debug-port;
                        xlnx,c6-c-s-axi-ctrl-addr-width = <0x20>;
                        xlnx,c5-ddr2-dq-width = <0x8>;
                        xlnx,c4-rldiii-ck-width = <0x1>;
                        xlnx,c7-rldii-dk-width = <0x1>;
                        xlnx,c7-c-s-axi-data-width = <0x20>;
                        xlnx,c0-lpddr2-cke-width = <0x1>;
                        xlnx,c6-c-s-axi-addr-width = <0x20>;
                        xlnx,c1-lpddr2-reg-ctrl;
                        xlnx,c1-ddr2-row-width = <0xe>;
                        xlnx,c7-rldii-addr-width = <0x1d>;
                        xlnx,c7-ddr2-ncs-per-rank = <0x1>;
                        xlnx,c6-ecc;
                        xlnx,c0-rldiii-rld-addr-width = <0x1d>;
                        xlnx,c0-ddr2-dq-width = <0x8>;
                        xlnx,c2-rldii-num-devices = <0x1>;
                        xlnx,ddr3-use-odt-port = <0x1>;
                        xlnx,c7-c-s-axi-mem-size = <0x100000>;
                        xlnx,c7-lpddr2-dq-width = <0x8>;
                        xlnx,c1-ddrx-addr-width = <0x8>;
                        xlnx,c4-ddr3-use-odt-port = <0x1>;
                        xlnx,c6-ddr2-ck-width = <0x1>;
                        xlnx,c1-mmcm-clkout1-en;
                        xlnx,c7-ddr3-cs-width = <0x1>;
                        xlnx,qdriip-data-width = <0x12>;
                        xlnx,c4-debug-port;
                        xlnx,rldiii-qvld-width = <0x1>;
                        xlnx,mmcm-clkout2-freq = <0x47868c00>;
                        xlnx,rldii-dm-width = <0x1>;
                        xlnx,c5-rldii-debug-port;
                        xlnx,ddr2-nck-per-clk = <0x4>;
                        xlnx,c4-qdriip-data-width = <0x12>;
                        xlnx,c0-rldii-qk-width = <0x8>;
                        xlnx,c4-mmcm-clkout2-freq = <0xa>;
                        xlnx,c4-rldiii-qvld-width = <0x1>;
                        xlnx,c3-c-s-axi-id-width = <0x4>;
                        xlnx,c5-ddr3-dqs-width = <0x1>;
                        xlnx,c1-ddr2-ck-width = <0x1>;
                        xlnx,c0-rldx-cmd-per-clk = <0x1>;
                        xlnx,c4-ddr3-cke-width = <0x1>;
                        xlnx,ddr3-row-width = <0xe>;
                        xlnx,c2-ddr3-cs-width = <0x1>;
                        xlnx,lpddr2-use-odt-port = <0x1>;
                        xlnx,c0-c-s-axi-ctrl-data-width = <0x20>;
                        xlnx,board-mig-param = "ddr2_sdram";
                        xlnx,c4-mmcm-clkout4-en;
                        xlnx,c7-rldiii-qk-width = <0x8>;
                        xlnx,ddr2-use-odt-port = <0x1>;
                        xlnx,c7-ddr3-odt-width = <0x1>;
                        xlnx,c6-rldii-data-width = <0x12>;
                        xlnx,c3-qdriip-bw-width = <0x8>;
                        xlnx,c6-rldii-bank-width = <0x2>;
                        xlnx,c2-qdriip-num-devices = <0x1>;
                        xlnx,c4-ddr2-use-odt-port = <0x1>;
                        xlnx,c4-rldii-qvld-width = <0x1>;
                        xlnx,c2-ddr2-dqs-cnt-width = <0x1>;
                        xlnx,ddr2-ck-width = <0x1>;
                        xlnx,c7-mem-type = "DDR3";
                        xlnx,c5-debug-port;
                        xlnx,c4-ui-extra-clocks;
                        xlnx,c1-lpddr2-row-width = <0xe>;
                        xlnx,c5-qdriip-num-devices = <0x1>;
                        xlnx,c3-rldiii-data-width = <0x12>;
                        xlnx,rldii-dk-width = <0x1>;
                        xlnx,c6-qdriip-debug-port;
                        xlnx,c1-rldii-ck-width = <0x1>;
                        xlnx,c5-ddr2-dqs-cnt-width = <0x1>;
                        xlnx,c0-ddrx-data-width = <0x8>;
                        xlnx,c3-rldiii-bank-width = <0x2>;
                        xlnx,c6-polarity = "ACTIVE_LOW";
                        xlnx,c0-ddr3-ncs-per-rank = <0x1>;
                        xlnx,c5-ddr2-dm-width = <0x1>;
                        xlnx,c6-rldx-addr-width = <0x1d>;
                        xlnx,c5-mmcm-clkout4-freq = <0xa>;
                        xlnx,c1-ddr2-odt-width = <0x1>;
                        xlnx,c2-lpddr2-data-width = <0x8>;
                        xlnx,c3-c-s-axi-ctrl-id-width = <0x4>;
                        xlnx,c5-rldiii-rld-addr-width = <0x1d>;
                        xlnx,c7-mmcm-clkout0-en;
                        xlnx,c7-ddr2-addr-width = <0x8>;
                        xlnx,c2-lpddr2-bank-width = <0x3>;
                        xlnx,c4-use-axi = <0x0>;
                        xlnx,c0-rldiii-nck-per-clk = <0x1>;
                        xlnx,c5-mmcm-clkout1-freq = <0xa>;
                        xlnx,c5-qdriip-addr-width = <0x1d>;
                        xlnx,c2-mmcm-clkout3-en;
                        xlnx,combined-interface = <0x0>;
                        xlnx,c7-sysclk-type = "DIFF";
                        xlnx,c6-debug-port;
                        xlnx,c0-ddr2-dm-width = <0x1>;
                        xlnx,c5-ddr3-reg-ctrl;
                        xlnx,c2-rldii-dm-width = <0x1>;
                        xlnx,c7-lpddr2-dm-width = <0x1>;
                        xlnx,c6-lpddr2-dqs-cnt-width = <0x1>;
                        xlnx,c4-ddr3-use-dm-port = <0x1>;
                        xlnx,c3-rldiii-nck-per-clk = <0x1>;
                        xlnx,c0-lpddr2-ncs-per-rank = <0x1>;
                        xlnx,c4-ddr3-use-cs-port = <0x1>;
                        xlnx,c5-rldiii-debug-port;
                        xlnx,c2-ddr3-row-width = <0xe>;
                        xlnx,c0-ddr2-ncs-per-rank = <0x1>;
                        xlnx,c0-ddr3-reg-ctrl;
                        xlnx,c4-mem-type = "DDR3";
                        xlnx,lpddr2-debug-port;
                        xlnx,ddr3-odt-width = <0x1>;
                        xlnx,c6-rldiii-nck-per-clk = <0x1>;
                        xlnx,rldiii-cmd-per-clk = <0x1>;
                        xlnx,c7-ddr3-addr-width = <0x8>;
                        xlnx,rldiii-addr-width = <0x1d>;
                        xlnx,c4-lpddr2-debug-port;
                        xlnx,c2-lpddr2-dqs-width = <0x1>;
                        xlnx,c7-ddr2-row-width = <0xe>;
                        xlnx,c6-rldiii-dm-width = <0x1>;
                        xlnx,c0-ddrx-nck-per-clk = <0x2>;
                        xlnx,c4-rldiii-addr-width = <0x1d>;
                        xlnx,c3-polarity = "ACTIVE_LOW";
                        xlnx,c5-ddr2-debug-port;
                        xlnx,c7-debug-port;
                        xlnx,c0-lpddr2-use-dm-port = <0x1>;
                        xlnx,c5-rldx-data-width = <0x12>;
                        xlnx,c6-mmcm-clkout3-freq = <0xa>;
                        xlnx,c5-rldx-bank-width = <0x2>;
                        xlnx,c6-ddr2-data-width = <0x8>;
                        xlnx,c5-ddr3-nck-per-clk = <0x2>;
                        xlnx,c7-c-s-axi-ctrl-data-width = <0x20>;
                        xlnx,c0-lpddr2-use-cs-port = <0x1>;
                        xlnx,c2-rldii-dk-width = <0x1>;
                        xlnx,c6-ddr2-bank-width = <0x3>;
                        xlnx,c3-lpddr2-addr-width = <0x8>;
                        xlnx,c5-ddr2-cs-width = <0x1>;
                        xlnx,c6-mmcm-clkout0-freq = <0xa>;
                        xlnx,c2-lpddr2-ck-width = <0x1>;
                        xlnx,c0-mmcm-clkout2-en;
                        xlnx,c3-lpddr2-use-dm-port = <0x1>;
                        xlnx,c4-rldii-addr-width = <0x1d>;
                        xlnx,mem-type = "DDR2";
                        xlnx,c1-lpddr2-ncs-per-rank = <0x1>;
                        xlnx,c6-rldii-qk-width = <0x8>;
                        xlnx,c1-rldiii-cmd-per-clk = <0x1>;
                        xlnx,c3-lpddr2-use-cs-port = <0x1>;
                        xlnx,c4-c-s-axi-mem-size = <0x100000>;
                        xlnx,c0-ddr2-cs-width = <0x1>;
                        xlnx,rldx-addr-width = <0x1d>;
                        xlnx,c7-lpddr2-cs-width = <0x1>;
                        xlnx,c1-mem-type = "DDR3";
                        xlnx,c6-lpddr2-use-dm-port = <0x1>;
                        xlnx,c5-ddr3-debug-port;
                        xlnx,c6-ddr3-dq-width = <0x8>;
                        xlnx,c6-rldx-nck-per-clk = <0x1>;
                        xlnx,c6-rldiii-dk-width = <0x1>;
                        xlnx,c6-ddr2-use-dm-port = <0x1>;
                        xlnx,c2-rldii-debug-port;
                        xlnx,c4-c-s-axi-ctrl-mem-size = <0x100000>;
                        xlnx,c6-lpddr2-use-cs-port = <0x1>;
                        xlnx,c4-c-s-axi-ctrl-addr-width = <0x20>;
                        xlnx,c4-rldiii-cmd-per-clk = <0x1>;
                        xlnx,c1-rldiii-ck-width = <0x1>;
                        xlnx,c5-rldii-num-devices = <0x1>;
                        xlnx,c6-ddr3-data-width = <0x8>;
                        xlnx,c0-ddr3-dqs-width = <0x1>;
                        xlnx,noofcontrollers = <0x1>;
                        xlnx,c6-ddr3-bank-width = <0x3>;
                        xlnx,c6-ddr2-use-cs-port = <0x1>;
                        xlnx,c0-c-s-axi-id-width = <0x4>;
                        xlnx,c7-ddr3-use-odt-port = <0x1>;
                        xlnx,c0-polarity = "ACTIVE_LOW";
                        xlnx,c6-mmcm-vco = <0x4b0>;
                        xlnx,c1-ddr3-dq-width = <0x8>;
                        xlnx,c7-rldiii-cmd-per-clk = <0x1>;
                        xlnx,c2-ddr3-odt-width = <0x1>;
                        xlnx,lpddr2-dqs-width = <0x1>;
                        xlnx,c2-rldii-nck-per-clk = <0x1>;
                        xlnx,c3-is-clk-shared;
                        xlnx,c7-rldii-ck-width = <0x1>;
                        xlnx,c6-rldx-dm-width = <0x1>;
                        xlnx,c6-lpddr2-reg-ctrl;
                        xlnx,c3-rldii-data-width = <0x12>;
                        xlnx,c4-lpddr2-dq-width = <0x8>;
                        xlnx,c5-ddr2-dqs-width = <0x1>;
                        xlnx,c7-qdriip-data-width = <0x12>;
                        xlnx,c7-ddr3-ck-width = <0x1>;
                        xlnx,c7-rldiii-qvld-width = <0x1>;
                        xlnx,c7-mmcm-clkout2-freq = <0xa>;
                        xlnx,c3-rldii-bank-width = <0x2>;
                        xlnx,c4-ddr2-cke-width = <0x1>;
                        xlnx,ddr2-row-width = <0xd>;
                        xlnx,c6-rldii-rld-addr-width = <0x1d>;
                        xlnx,c1-rldii-qvld-width = <0x1>;
                        xlnx,c2-lpddr2-ncs-per-rank = <0x1>;
                        xlnx,c1-rldii-cmd-per-clk = <0x1>;
                        xlnx,ddr3-dq-width = <0x8>;
                        xlnx,c7-ddr2-odt-width = <0x1>;
                        xlnx,c6-ddrx-addr-width = <0x8>;
                        xlnx,c1-rldx-dm-width = <0x1>;
                        xlnx,c7-ddr2-nck-per-clk = <0x2>;
                        xlnx,c2-ddr3-ck-width = <0x1>;
                        xlnx,c5-qdriip-burst-len = <0x1>;
                        xlnx,rldiii-dm-width = <0x1>;
                        xlnx,c6-mmcm-clkout1-en;
                        xlnx,c7-ddr2-use-odt-port = <0x1>;
                        xlnx,c3-ddr2-reg-ctrl;
                        xlnx,c1-mmcm-clkout4-en;
                        xlnx,c4-rldiii-qk-width = <0x8>;
                        xlnx,ddr2-data-width = <0x10>;
                        xlnx,ddr2-bank-width = <0x3>;
                        xlnx,c0-qdriip-bw-width = <0x8>;
                        xlnx,rldx-dm-width = <0x1>;
                        xlnx,c2-lpddr2-nck-per-clk = <0x2>;
                        xlnx,c6-rldiii-data-width = <0x12>;
                        xlnx,c2-freq-hz = <0x64>;
                        xlnx,c6-rldiii-bank-width = <0x2>;
                        xlnx,c0-ddr3-dqs-cnt-width = <0x1>;
                        xlnx,rldii-debug-port;
                        xlnx,c3-mmcm-vco = <0x4b0>;
                        xlnx,c1-ui-extra-clocks;
                        xlnx,c5-dqs-cnt-width = <0x1>;
                        xlnx,rable = <0x0>;
                        xlnx,c3-ddr3-ncs-per-rank = <0x1>;
                        xlnx,c1-ddr3-use-dm-port = <0x1>;
                        xlnx,c3-lpddr2-ncs-per-rank = <0x1>;
                        xlnx,c5-lpddr2-data-width = <0x8>;
                        xlnx,c5-lpddr2-nck-per-clk = <0x2>;
                        xlnx,c5-lpddr2-cke-width = <0x1>;
                        xlnx,c5-lpddr2-bank-width = <0x3>;
                        xlnx,c3-ddr3-dqs-cnt-width = <0x1>;
                        xlnx,c1-ddr3-use-cs-port = <0x1>;
                        xlnx,rldiii-dk-width = <0x1>;
                        xlnx,c6-ddr3-dm-width = <0x1>;
                        xlnx,c0-dqs-cnt-width = <0x1>;
                        xlnx,ddr3-data-width = <0x8>;
                        xlnx,c3-rldx-addr-width = <0x1d>;
                        xlnx,ddr3-bank-width = <0x3>;
                        xlnx,c5-ddrx-data-width = <0x8>;
                        xlnx,rldii-ck-width = <0x1>;
                        xlnx,c4-ddr2-addr-width = <0x8>;
                        xlnx,c4-mmcm-clkout0-en;
                        xlnx,c6-ddr3-dqs-cnt-width = <0x1>;
                        xlnx,c2-ddr2-row-width = <0xe>;
                        xlnx,c1-ddr3-dm-width = <0x1>;
                        xlnx,c3-sysclk-type = "DIFF";
                        xlnx,lpddr2-reg-ctrl;
                        xlnx,ddr2-odt-width = <0x1>;
                        xlnx,c3-ddr2-ncs-per-rank = <0x1>;
                        xlnx,c4-ecc;
                        xlnx,c4-lpddr2-dm-width = <0x1>;
                        xlnx,c7-mmcm-clkout3-en;
                        xlnx,c2-ddr3-nck-per-clk = <0x2>;
                        xlnx,c5-rldx-cmd-per-clk = <0x1>;
                        xlnx,c7-lpddr2-debug-port;
                        xlnx,c0-ddr3-use-odt-port = <0x1>;
                        xlnx,ddrx-addr-width = <0x8>;
                        xlnx,c0-mmcm-vco = <0x4b0>;
                        xlnx,c3-lpddr2-dqs-cnt-width = <0x1>;
                        xlnx,c4-ddr2-dq-width = <0x8>;
                        xlnx,ddr3-dm-width = <0x1>;
                        xlnx,c7-rldiii-addr-width = <0x1d>;
                        xlnx,mmcm-clkout1-en;
                        xlnx,c1-rldii-addr-width = <0x1d>;
                        xlnx,c4-lpddr2-ncs-per-rank = <0x1>;
                        xlnx,c1-rldii-qk-width = <0x8>;
                        xlnx,c6-ddr3-dqs-width = <0x1>;
                        xlnx,c0-qdriip-data-width = <0x12>;
                        xlnx,c0-rldiii-qvld-width = <0x1>;
                        xlnx,c0-mmcm-clkout2-freq = <0xa>;
                        xlnx,c4-ddr3-addr-width = <0x8>;
                        xlnx,c1-c-s-axi-mem-size = <0x100000>;
                        xlnx,c5-ddr3-cke-width = <0x1>;
                        xlnx,c6-lpddr2-addr-width = <0x8>;
                        xlnx,c3-rldiii-dm-width = <0x1>;
                        xlnx,c2-ddr2-debug-port;
                        xlnx,c6-lpddr2-row-width = <0xe>;
                        xlnx,c0-lpddr2-use-odt-port = <0x1>;
                        xlnx,c2-rldx-data-width = <0x12>;
                        xlnx,c3-ddr2-use-dm-port = <0x1>;
                        xlnx,c3-rldx-nck-per-clk = <0x1>;
                        xlnx,c5-ddr2-ck-width = <0x1>;
                        xlnx,c2-rldx-bank-width = <0x2>;
                        xlnx,s-axi-ctrl-id-width = <0x4>;
                        xlnx,c6-ddr3-cs-width = <0x1>;
                        xlnx,c3-ddr2-data-width = <0x8>;
                        xlnx,c0-ddr2-use-odt-port = <0x1>;
                        xlnx,c3-ddr2-bank-width = <0x3>;
                        xlnx,c5-c-s-axi-ctrl-data-width = <0x20>;
                        xlnx,c3-ddr2-use-cs-port = <0x1>;
                        xlnx,c0-c-s-axi-ctrl-id-width = <0x4>;
                        xlnx,c2-rldiii-rld-addr-width = <0x1d>;
                        xlnx,c7-freq-hz = <0x64>;
                        xlnx,c0-ddr2-ck-width = <0x1>;
                        xlnx,c1-ddr3-cs-width = <0x1>;
                        xlnx,c0-ddr2-dqs-width = <0x1>;
                        xlnx,c2-rldii-ck-width = <0x1>;
                        xlnx,c7-lpddr2-ck-width = <0x1>;
                        xlnx,c0-rldii-data-width = <0x12>;
                        xlnx,c5-mmcm-clkout2-en;
                        xlnx,debug-port;
                        xlnx,c2-qdriip-debug-port;
                        xlnx,c0-rldii-bank-width = <0x2>;
                        xlnx,c5-lpddr2-ncs-per-rank = <0x1>;
                        xlnx,c4-lpddr2-cs-width = <0x1>;
                        xlnx,c2-ddr3-debug-port;
                        xlnx,c2-ddr2-odt-width = <0x1>;
                        xlnx,ddr3-nck-per-clk = <0x2>;
                        xlnx,c1-mmcm-clkout4-freq = <0xa>;
                        xlnx,c3-rldiii-dk-width = <0x1>;
                        xlnx,c2-c-s-axi-ctrl-addr-width = <0x20>;
                        xlnx,c2-qdriip-burst-len = <0x1>;
                        xlnx,c3-ddr3-data-width = <0x8>;
                        xlnx,c4-ddr2-nck-per-clk = <0x2>;
                        xlnx,ddr3-cs-width = <0x1>;
                        xlnx,c5-rldii-nck-per-clk = <0x1>;
                        xlnx,c1-mmcm-clkout1-freq = <0xa>;
                        xlnx,c3-ddr3-bank-width = <0x3>;
                        xlnx,c1-qdriip-addr-width = <0x1d>;
                        xlnx,c3-use-axi = <0x0>;
                        xlnx,rldii-cmd-per-clk = <0x1>;
                        xlnx,c1-lpddr2-use-odt-port = <0x1>;
                        xlnx,rldiii-num-devices = <0x1>;
                        xlnx,c3-rldii-dm-width = <0x1>;
                        xlnx,xml-input-file = "mig_a.prj";
                        xlnx,c6-rldiii-ck-width = <0x1>;
                        xlnx,c4-rldii-cmd-per-clk = <0x1>;
                        xlnx,c1-lpddr2-dq-width = <0x8>;
                        xlnx,c3-lpddr2-reg-ctrl;
                        xlnx,c7-lpddr2-dqs-width = <0x1>;
                        xlnx,edk-special = "MEMORY_CTRL";
                        xlnx,c3-ddr3-row-width = <0xe>;
                        xlnx,c4-ddr2-dm-width = <0x1>;
                        xlnx,c5-ddrx-nck-per-clk = <0x2>;
                        xlnx,c1-rldiii-debug-port;
                        xlnx,c3-ddrx-addr-width = <0x8>;
                        xlnx,c3-rldii-rld-addr-width = <0x1d>;
                        xlnx,c6-lpddr2-ncs-per-rank = <0x1>;
                        xlnx,c3-mmcm-clkout1-en;
                        xlnx,c0-lpddr2-debug-port;
                        xlnx,c4-ddr3-reg-ctrl;
                        xlnx,c2-lpddr2-cke-width = <0x1>;
                        xlnx,c0-rldiii-addr-width = <0x1d>;
                        xlnx,c1-rldiii-num-devices = <0x1>;
                        xlnx,c1-rldiii-qk-width = <0x8>;
                        xlnx,c7-rldiii-rld-addr-width = <0x1d>;
                        xlnx,c3-rldii-dk-width = <0x1>;
                        xlnx,c5-c-s-axi-ctrl-id-width = <0x4>;
                        xlnx,c6-ddr3-ncs-per-rank = <0x1>;
                        xlnx,c2-mmcm-clkout3-freq = <0xa>;
                        xlnx,c2-lpddr2-use-odt-port = <0x1>;
                        xlnx,c6-mmcm-clkout4-en;
                        xlnx,c2-mmcm-clkout0-freq = <0xa>;
                        xlnx,c4-rldiii-num-devices = <0x1>;
                        xlnx,c7-rldii-qk-width = <0x8>;
                        xlnx,c7-rldii-debug-port;
                        xlnx,c1-c-s-axi-ctrl-mem-size = <0x100000>;
                        xlnx,c5-qdriip-bw-width = <0x8>;
                        xlnx,qdriip-burst-len = <0x1>;
                        xlnx,c5-c-s-axi-id-width = <0x4>;
                        xlnx,c2-rldx-cmd-per-clk = <0x1>;
                        xlnx,c7-rldiii-num-devices = <0x1>;
                        xlnx,c6-ui-extra-clocks;
                        xlnx,c7-lpddr2-ncs-per-rank = <0x1>;
                        xlnx,c0-rldx-addr-width = <0x1d>;
                        xlnx,c6-ddr2-ncs-per-rank = <0x1>;
                        xlnx,c1-ddr3-dqs-width = <0x1>;
                        xlnx,c2-ddrx-data-width = <0x8>;
                        xlnx,c4-ddr2-cs-width = <0x1>;
                        xlnx,c1-ddr2-addr-width = <0x8>;
                        xlnx,c0-ddr3-cke-width = <0x1>;
                        xlnx,c1-mmcm-clkout0-en;
                        xlnx,c1-rldii-num-devices = <0x1>;
                        xlnx,c6-rldii-qvld-width = <0x1>;
                        xlnx,rldiii-ck-width = <0x1>;
                        xlnx,c3-ddr3-use-odt-port = <0x1>;
                        xlnx,c3-ddr3-odt-width = <0x1>;
                        xlnx,c3-lpddr2-use-odt-port = <0x1>;
                        xlnx,c6-ddr2-dqs-width = <0x1>;
                        xlnx,c1-lpddr2-dm-width = <0x1>;
                        xlnx,lpddr2-cke-width = <0x1>;
                        xlnx,c3-lpddr2-row-width = <0xe>;
                        xlnx,c0-rldx-nck-per-clk = <0x1>;
                        xlnx,c0-ddr2-use-dm-port = <0x1>;
                        xlnx,c5-ddr2-cke-width = <0x1>;
                        xlnx,c1-c-s-axi-addr-width = <0x20>;
                        xlnx,c2-c-s-axi-data-width = <0x20>;
                        xlnx,c3-qdriip-data-width = <0x12>;
                        xlnx,c4-mmcm-clkout3-en;
                        xlnx,phase = <0x0>;
                        xlnx,c3-mmcm-clkout2-freq = <0xa>;
                        xlnx,c3-rldiii-qvld-width = <0x1>;
                        xlnx,c5-ddr3-dq-width = <0x8>;
                        xlnx,c0-ddr2-use-cs-port = <0x1>;
                        xlnx,c7-is-clk-shared;
                        xlnx,c1-ddr3-addr-width = <0x8>;
                        xlnx,c4-c-s-axi-addr-width = <0x20>;
                        xlnx,c5-c-s-axi-data-width = <0x20>;
                        xlnx,c0-lpddr2-dqs-cnt-width = <0x1>;
                        xlnx,c0-ddr3-dq-width = <0x8>;
                        xlnx,c3-ddr2-use-odt-port = <0x1>;
                        xlnx,c0-rldiii-dm-width = <0x1>;
                        xlnx,c2-is-clk-shared;
                        xlnx,rldii-qk-width = <0x8>;
                        xlnx,c5-rldx-dm-width = <0x1>;
                        xlnx,c6-ddr3-ck-width = <0x1>;
                        xlnx,mmcm-clkout4-en;
                        xlnx,c6-ddr3-use-dm-port = <0x1>;
                        xlnx,rldx-cmd-per-clk = <0x1>;
                        xlnx,c7-c-s-axi-addr-width = <0x20>;
                        xlnx,c6-c-s-axi-ctrl-mem-size = <0x100000>;
                        xlnx,sysclk-type = "NOBUF";
                        xlnx,c7-ddr2-reg-ctrl;
                        xlnx,c0-ddr2-data-width = <0x8>;
                        xlnx,c7-ddr2-debug-port;
                        xlnx,c1-ddr2-nck-per-clk = <0x2>;
                        xlnx,c6-ddr3-use-cs-port = <0x1>;
                        xlnx,c0-ddr2-bank-width = <0x3>;
                        xlnx,c2-rldiii-data-width = <0x12>;
                        xlnx,c3-c-s-axi-ctrl-data-width = <0x20>;
                        xlnx,c4-lpddr2-use-odt-port = <0x1>;
                        xlnx,c5-qdriip-debug-port;
                        xlnx,freq-hz = <0x4d7bee1>;
                        xlnx,c7-rldx-data-width = <0x12>;
                        xlnx,c0-rldx-dm-width = <0x1>;
                        xlnx,c2-rldiii-bank-width = <0x2>;
                        xlnx,c1-freq-hz = <0x64>;
                        xlnx,c1-ddr3-ck-width = <0x1>;
                        xlnx,c7-rldx-bank-width = <0x2>;
                        xlnx,mmcm-clkout4-freq = <0x47868c00>;
                        xlnx,ui-extra-clocks;
                        xlnx,c2-ddr2-reg-ctrl;
                        xlnx,c4-lpddr2-ck-width = <0x1>;
                        xlnx,c4-mmcm-clkout4-freq = <0xa>;
                        xlnx,mmcm-clkout1-freq = <0x47868c00>;
                        xlnx,c1-lpddr2-data-width = <0x8>;
                        xlnx,c2-mmcm-clkout2-en;
                        xlnx,qdriip-addr-width = <0x1d>;
                        xlnx,c4-lpddr2-dqs-width = <0x1>;
                        xlnx,c1-lpddr2-bank-width = <0x3>;
                        xlnx,c2-ddrx-nck-per-clk = <0x2>;
                        xlnx,c1-lpddr2-cs-width = <0x1>;
                        xlnx,c4-mmcm-clkout1-freq = <0xa>;
                        xlnx,c4-qdriip-addr-width = <0x1d>;
                        xlnx,c7-lpddr2-dqs-cnt-width = <0x1>;
                        xlnx,ddr3-ck-width = <0x1>;
                        xlnx,c0-rldiii-dk-width = <0x1>;
                        xlnx,c0-qdriip-num-devices = <0x1>;
                        xlnx,c7-rldii-cmd-per-clk = <0x1>;
                        xlnx,c7-ddr3-nck-per-clk = <0x2>;
                        xlnx,c0-ddr2-dqs-cnt-width = <0x1>;
                        xlnx,c0-c-s-axi-ctrl-addr-width = <0x20>;
                        xlnx,c0-ddr3-data-width = <0x8>;
                        xlnx,c3-ddr2-row-width = <0xe>;
                        xlnx,c7-ddr3-debug-port;
                        xlnx,rldiii-debug-port;
                        xlnx,c0-ddr3-bank-width = <0x3>;
                        xlnx,c4-dqs-cnt-width = <0x1>;
                        xlnx,c6-rldii-addr-width = <0x1d>;
                        xlnx,c4-rldiii-debug-port;
                        xlnx,c3-rldiii-ck-width = <0x1>;
                        xlnx,rldiii-nck-per-clk = <0x1>;
                        xlnx,c3-qdriip-num-devices = <0x1>;
                        xlnx,ecc;
                        xlnx,c7-polarity = "ACTIVE_LOW";
                        xlnx,c3-ddr2-dqs-cnt-width = <0x1>;
                        xlnx,c6-c-s-axi-mem-size = <0x100000>;
                        xlnx,c0-lpddr2-reg-ctrl;
                        xlnx,c2-ecc;
                        xlnx,c5-ddr3-dm-width = <0x1>;
                        xlnx,c5-lpddr2-use-odt-port = <0x1>;
                        xlnx,s-axi-mem-size = <0x8000000>;
                        xlnx,c3-lpddr2-debug-port;
                        xlnx,c6-qdriip-num-devices = <0x1>;
                        xlnx,c2-rldii-qk-width = <0x8>;
                        xlnx,c6-lpddr2-dq-width = <0x8>;
                        xlnx,c3-rldiii-addr-width = <0x1d>;
                        xlnx,c7-ddr3-dqs-width = <0x1>;
                        xlnx,c6-ddr2-dqs-cnt-width = <0x1>;
                        xlnx,c4-rldii-debug-port;
                        xlnx,c0-ddrx-addr-width = <0x8>;
                        xlnx,c6-ddr3-cke-width = <0x1>;
                        xlnx,c0-ddr3-dm-width = <0x1>;
                        xlnx,c0-mmcm-clkout1-en;
                        xlnx,c2-c-s-axi-id-width = <0x4>;
                        xlnx,c5-mmcm-clkout3-freq = <0xa>;
                        xlnx,c2-lpddr2-addr-width = <0x8>;
                        xlnx,s-axi-ctrl-data-width = <0x20>;
                        xlnx,c0-rldii-rld-addr-width = <0x1d>;
                        xlnx,c5-mmcm-clkout0-freq = <0xa>;
                        xlnx,c1-rldiii-nck-per-clk = <0x1>;
                        xlnx,c5-mem-type = "DDR3";
                        xlnx,c5-rldii-data-width = <0x12>;
                        xlnx,ddrx-nck-per-clk = <0x2>;
                        xlnx,c3-ddr2-dq-width = <0x8>;
                        xlnx,c5-rldii-bank-width = <0x2>;
                        xlnx,c7-phase = <0x0>;
                        xlnx,c3-mmcm-clkout4-en;
                        xlnx,c3-rldii-qvld-width = <0x1>;
                        xlnx,c6-rldiii-qk-width = <0x8>;
                        xlnx,lpddr2-use-dm-port = <0x1>;
                        xlnx,c4-sysclk-type = "DIFF";
                        xlnx,c4-rldiii-nck-per-clk = <0x1>;
                        xlnx,c6-lpddr2-use-odt-port = <0x1>;
                        xlnx,c2-qdriip-bw-width = <0x8>;
                        xlnx,lpddr2-use-cs-port = <0x1>;
                        xlnx,c1-ddr2-dqs-width = <0x1>;
                        xlnx,c3-rldii-ck-width = <0x1>;
                        xlnx,c4-polarity = "ACTIVE_LOW";
                        xlnx,rldii-num-devices = <0x1>;
                        xlnx,c7-qdriip-burst-len = <0x1>;
                        xlnx,c0-ddr2-cke-width = <0x1>;
                        xlnx,c7-ecc;
                        xlnx,c0-lpddr2-row-width = <0xe>;
                        xlnx,c6-freq-hz = <0x64>;
                        xlnx,c4-rldii-num-devices = <0x1>;
                        xlnx,c3-ui-extra-clocks;
                        xlnx,c6-phase = <0x0>;
                        xlnx,c7-rldiii-nck-per-clk = <0x1>;
                        xlnx,c3-ddr2-odt-width = <0x1>;
                        xlnx,c4-ddr2-ck-width = <0x1>;
                        xlnx,c5-ddr3-cs-width = <0x1>;
                        xlnx,c6-ddr3-use-odt-port = <0x1>;
                        xlnx,c7-rldii-rld-addr-width = <0x1d>;
                        xlnx,c1-rldii-nck-per-clk = <0x1>;
                        xlnx,c6-qdriip-data-width = <0x12>;
                        xlnx,c1-lpddr2-use-dm-port = <0x1>;
                        xlnx,c4-rldii-dm-width = <0x1>;
                        xlnx,c6-rldiii-qvld-width = <0x1>;
                        xlnx,c6-mmcm-clkout2-freq = <0xa>;
                        xlnx,c5-rldx-addr-width = <0x1d>;
                        xlnx,c7-ddrx-data-width = <0x8>;
                        xlnx,c0-ddr3-cs-width = <0x1>;
                        xlnx,c2-use-axi = <0x0>;
                        xlnx,c5-phase = <0x0>;
                        xlnx,ddr3-dqs-width = <0x1>;
                        xlnx,c6-mmcm-clkout0-en;
                        xlnx,c6-ddr2-addr-width = <0x8>;
                        xlnx,c7-c-s-axi-ctrl-addr-width = <0x20>;
                        xlnx,c0-rldii-cmd-per-clk = <0x1>;
                        xlnx,c1-lpddr2-use-cs-port = <0x1>;
                        xlnx,c2-mem-type = "DDR3";
                        xlnx,c3-ddr3-use-dm-port = <0x1>;
                        xlnx,c4-ddr3-row-width = <0xe>;
                        xlnx,polarity = "ACTIVE_LOW";
                        xlnx,c7-lpddr2-cke-width = <0x1>;
                        xlnx,c1-mmcm-clkout3-en;
                        xlnx,c4-lpddr2-use-dm-port = <0x1>;
                        xlnx,lpddr2-dq-width = <0x8>;
                        xlnx,c7-lpddr2-use-odt-port = <0x1>;
                        xlnx,c3-ddr3-use-cs-port = <0x1>;
                        xlnx,c6-lpddr2-dm-width = <0x1>;
                        xlnx,c6-ddr2-use-odt-port = <0x1>;
                        xlnx,c2-rldiii-cmd-per-clk = <0x1>;
                        xlnx,c4-lpddr2-use-cs-port = <0x1>;
                        xlnx,c1-polarity = "ACTIVE_LOW";
                        xlnx,c2-c-s-axi-ctrl-id-width = <0x4>;
                        xlnx,c4-phase = <0x0>;
                        xlnx,c4-rldiii-rld-addr-width = <0x1d>;
                        xlnx,refclk-type = "NOBUF";
                        xlnx,c7-mmcm-vco = <0x4b0>;
                        xlnx,c7-lpddr2-use-dm-port = <0x1>;
                        xlnx,c1-lpddr2-dqs-width = <0x1>;
                        xlnx,c7-lpddr2-use-cs-port = <0x1>;
                        xlnx,c5-rldiii-cmd-per-clk = <0x1>;
                        xlnx,c5-rldiii-data-width = <0x12>;
                        xlnx,c6-ddr3-addr-width = <0x8>;
                        xlnx,c5-rldiii-bank-width = <0x2>;
                        xlnx,c4-rldii-dk-width = <0x1>;
                        xlnx,c3-ddr2-dm-width = <0x1>;
                        xlnx,rldiii-qk-width = <0x8>;
                        xlnx,lpddr2-data-width = <0x8>;
                        xlnx,c3-phase = <0x0>;
                        xlnx,c7-rldx-cmd-per-clk = <0x1>;
                        xlnx,c2-ddr3-ncs-per-rank = <0x1>;
                        xlnx,c4-ddr3-nck-per-clk = <0x2>;
                        xlnx,c5-rldiii-dm-width = <0x1>;
                        xlnx,lpddr2-bank-width = <0x3>;
                        xlnx,c4-ddr2-debug-port;
                        xlnx,c7-mmcm-clkout4-freq = <0xa>;
                        xlnx,c4-lpddr2-data-width = <0x8>;
                        xlnx,c1-c-s-axi-ctrl-data-width = <0x20>;
                        xlnx,c4-lpddr2-bank-width = <0x3>;
                        xlnx,c4-rldx-data-width = <0x12>;
                        xlnx,c7-mmcm-clkout1-freq = <0xa>;
                        xlnx,c3-rldii-addr-width = <0x1d>;
                        xlnx,c4-rldx-bank-width = <0x2>;
                        xlnx,c7-qdriip-addr-width = <0x1d>;
                        xlnx,c3-ddr3-reg-ctrl;
                        xlnx,c5-ddr2-data-width = <0x8>;
                        xlnx,c5-ddr2-bank-width = <0x3>;
                        xlnx,ddr3-dqs-cnt-width = <0x1>;
                        xlnx,c1-lpddr2-ck-width = <0x1>;
                        xlnx,c3-c-s-axi-mem-size = <0x100000>;
                        phandle = <0xe>;
                };
        };

        microblaze_0_local_memory_dlmb_bram_if_cntlr_memory: memory@0 {
                compatible = "xlnx,lmb-bram-if-cntlr-4.0";
                device_type = "memory";
                reg = <0x0 0x8000>;
                phandle = <0x1>;
        };

        mig_7series_0_memory: memory@0x80000000 {
                compatible = "xlnx,mig-7series-4.2";
                device_type = "memory";
                reg = <0x80000000 0x8000000>;
                phandle = <0x2>;
        };

        chosen {
                stdout-path = "serial0:9600n8";
        };

        aliases {
                serial0 = "/amba_pl/axi_uartlite@40600000";
        };

        __symbols__ {
                clock = "/clocks";
                clk_cpu = "/clocks/clk_cpu@0";
                clk_bus_0 = "/clocks/clk_bus_0@1";
                amba_pl = "/amba_pl";
                cpus_microblaze_0 = "/amba_pl/cpus_microblaze@0";
                microblaze_0 = "/amba_pl/cpus_microblaze@0/cpu@0";
                axi_uartlite_0 = "/amba_pl/axi_uartlite@40600000";
                gpio_led = "/amba_pl/axi_gpio@40000000";
                gpio_sw = "/amba_pl/axi_gpio@40010000";
                microblaze_0_local_memory_dlmb_bram_if_cntlr = "/amba_pl/lmb_bram_if_cntlr@0";
                microblaze_0_local_memory_ilmb_bram_if_cntlr = "/amba_pl/lmb_bram_if_cntlr@1";
                mig_7series_0 = "/amba_pl/mig_7series@80000000";
                microblaze_0_local_memory_dlmb_bram_if_cntlr_memory = "/memory@0";
                mig_7series_0_memory = "/memory@0x80000000";
        };
};
